# cc13x2_cc26x2 register map
File version: 2.1
CPU: CM4 r0p1, little endian, MPU, FPU, 3 interrupt priority bits
Registers are 32-bit, read-write, reset 0x0 unless marked. A register's access mark holds for its fields unless they carry their own. Offsets are from the block's base; [hi:lo] are bit positions; {n}, {i} and the like mark numbered series.

## AON_BATMON — Always On (AON) Battery And Temperature MONitor (BATMON) residing in the AON domain Note: This module only supports 32 bit Read/Write access from MCU.
Base 0x40095000
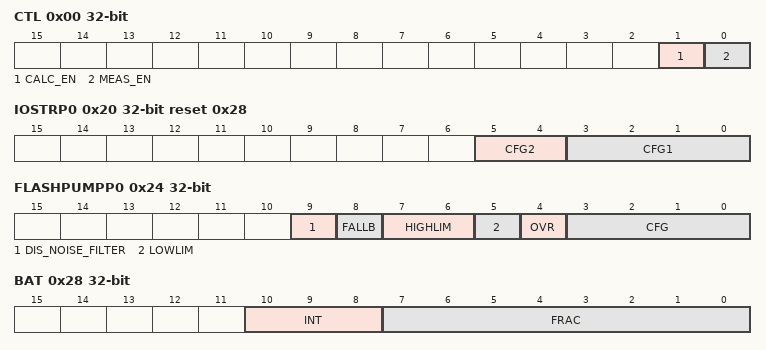
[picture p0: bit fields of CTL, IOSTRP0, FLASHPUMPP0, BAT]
0x00 CTL — Internal. Only to be used through TI provided API.
  [1] CALC_EN, [0] MEAS_EN
0x04 MEASCFG — Internal. Only to be used through TI provided API.
  [1:0] PER
0x0C TEMPP0 — Internal. Only to be used through TI provided API.
  [7:0] CFG
0x10 TEMPP1 — Internal. Only to be used through TI provided API.
  [5:0] CFG
0x14 TEMPP2 — Internal. Only to be used through TI provided API.
  [4:0] CFG
0x18 BATMONP0 — Internal. Only to be used through TI provided API.
  [6:0] CFG
0x1C BATMONP1 — Internal. Only to be used through TI provided API.
  [5:0] CFG
0x20 IOSTRP0 reset 0x28 — Internal. Only to be used through TI provided API.
  [5:4] CFG2, [3:0] CFG1
0x24 FLASHPUMPP0 — Internal. Only to be used through TI provided API.
  [9] DIS_NOISE_FILTER, [8] FALLB, [7:6] HIGHLIM, [5] LOWLIM, [4] OVR, [3:0] CFG
0x28 BAT ro — Last Measured Battery Voltage his register may be read while BATUPD.STAT = 1
  [10:8] INT, [7:0] FRAC
0x2C BATUPD — Battery Update ndicates BAT Updates
  [0] STAT write-1-clears
0x30 TEMP ro — Temperature ast Measured Temperature in Degrees Celsius his register may be read while TEMPUPD.STAT = 1.
  [16:8] INT
0x34 TEMPUPD — Temperature Update ndicates TEMP Updates
  [0] STAT write-1-clears
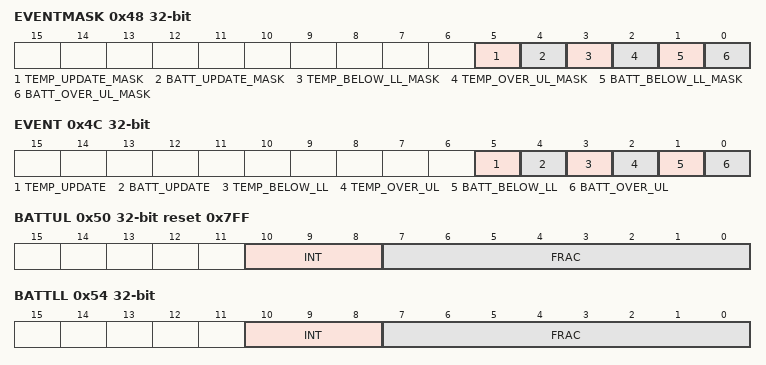
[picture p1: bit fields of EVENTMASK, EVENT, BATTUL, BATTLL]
0x48 EVENTMASK
  [5] TEMP_UPDATE_MASK, [4] BATT_UPDATE_MASK, [3] TEMP_BELOW_LL_MASK, [2] TEMP_OVER_UL_MASK, [1] BATT_BELOW_LL_MASK, [0] BATT_OVER_UL_MASK
0x4C EVENT
  [5] TEMP_UPDATE write-1-clears, [4] BATT_UPDATE write-1-clears, [3] TEMP_BELOW_LL write-1-clears, [2] TEMP_OVER_UL write-1-clears, [1] BATT_BELOW_LL write-1-clears, [0] BATT_OVER_UL write-1-clears
0x50 BATTUL reset 0x7FF — Battery Upper Limit
  [10:8] INT, [7:0] FRAC
0x54 BATTLL — Battery Lower Limit
  [10:8] INT, [7:0] FRAC
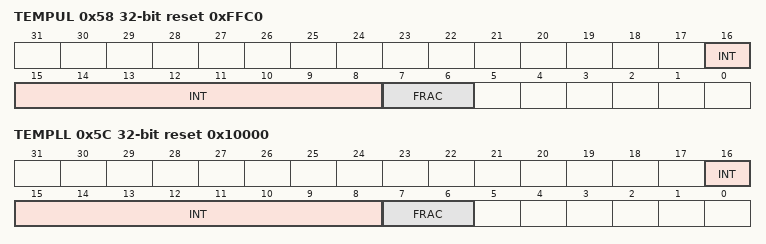
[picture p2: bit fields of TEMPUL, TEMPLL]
0x58 TEMPUL reset 0xFFC0 — Temperature Upper Limit
  [16:8] INT, [7:6] FRAC
0x5C TEMPLL reset 0x10000 — Temperature Lower Limit
  [16:8] INT, [7:6] FRAC

## AON_EVENT — This module configures the event fabric located in the AON domain. ote: This module is only supporting 32 bit ReadWrite access from MCU
Base 0x40093000
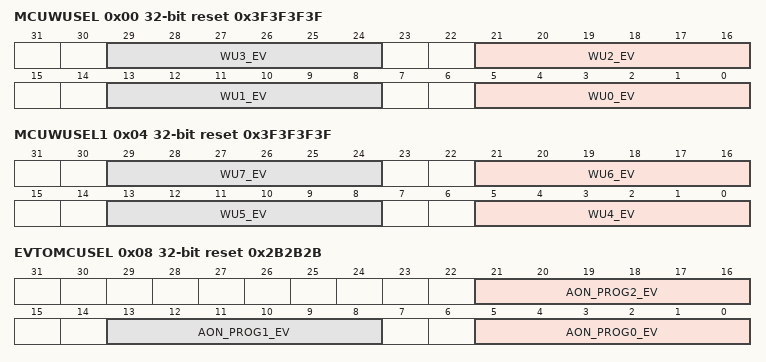
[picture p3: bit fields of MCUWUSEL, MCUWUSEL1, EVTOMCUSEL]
0x00 MCUWUSEL reset 0x3F3F3F3F — Wake-up Selector For MCU his register contains pointers to 4 of 8 events (events 0 to 3) which are routed to AON_PMCTRL as wakeup sources for MCU. AON_PMCTRL will start a wakeup sequence for the MCU domain when either of the 8 selected events are asserted. A wakeup sequence will guarantee that the MCU power switches are turned on, LDO resources are available and SCLK_HF is available and selected as clock source for MCU. ote: It is required to setup a wakeup event in AON_EVENT before MCU is requesting powerdown ( PRCM requests uLDO, see conditions in PRCM:VDCTL.ULDO ).
  [8n+5:8n] WU{n}_EV (n=0..3)
0x04 MCUWUSEL1 reset 0x3F3F3F3F — Wake-up Selector For MCU his register contains pointers to 4 of 8 events (events 4 to 7) which are routed to AON_PMCTRL as wakeup sources for MCU. AON_PMCTRL will start a wakeup sequence for the MCU domain when either of the 8 selected events are asserted. A wakeup sequence will guarantee that the MCU power switches are turned on, LDO resources are available and SCLK_HF is available and selected as clock source for MCU. ote: It is required to setup a wakeup event in AON_EVENT before MCU is requesting powerdown ( PRCM requests uLDO, see conditions in PRCM:VDCTL.ULDO ).
  [8n-27:8n-32] WU{n}_EV (n=4..7)
0x08 EVTOMCUSEL reset 0x2B2B2B — Event Selector For MCU Event Fabric his register contains pointers for 3 AON events that are routed to the MCU Event Fabric EVENT
  [21:16] AON_PROG2_EV, [13:8] AON_PROG1_EV, [5:0] AON_PROG0_EV
0x0C RTCSEL reset 0x3F — RTC Capture Event Selector For AON_RTC his register contains a pointer to select an AON event for RTC capture. Please refer to AON_RTC:CH1CAPT
  [5:0] RTC_CH1_CAPT_EV
